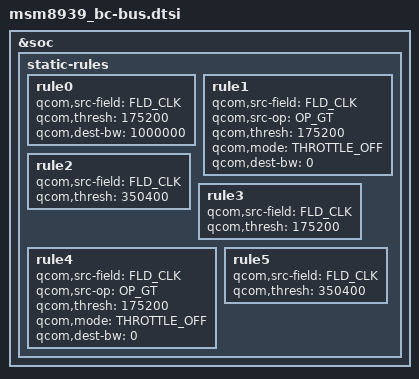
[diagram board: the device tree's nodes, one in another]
/*
 * Copyright (c) 2015, The Linux Foundation. All rights reserved.
 *
 * This program is free software; you can redistribute it and/or modify
 * it under the terms of the GNU General Public License version 2 and
 * only version 2 as published by the Free Software Foundation.
 *
 * This program is distributed in the hope that it will be useful,
 * but WITHOUT ANY WARRANTY; without even the implied warranty of
 * MERCHANTABILITY or FITNESS FOR A PARTICULAR PURPOSE.  See the
 * GNU General Public License for more details.
 */

#include "../msm8939-bus.dtsi"

&soc {
	static-rules {
		rule0 {
			qcom,src-field = <FLD_CLK>;
			qcom,thresh = <175200>;
			qcom,dest-bw = <1000000>;
		};

		rule1 {
			qcom,src-field = <FLD_CLK>;
			qcom,src-op = <OP_GT>;
			qcom,thresh = <175200>;
			qcom,mode = <THROTTLE_OFF>;
			qcom,dest-bw = <0>;
		};

		rule2 {
			qcom,src-field = <FLD_CLK>;
			qcom,thresh = <350400>;
		};

		rule3 {
			qcom,src-field = <FLD_CLK>;
			qcom,thresh = <175200>;
		};

		rule4 {
			qcom,src-field = <FLD_CLK>;
			qcom,src-op = <OP_GT>;
			qcom,thresh = <175200>;
			qcom,mode = <THROTTLE_OFF>;
			qcom,dest-bw = <0>;
		};

		rule5 {
			qcom,src-field = <FLD_CLK>;
			qcom,thresh = <350400>;
		};
	};
};
